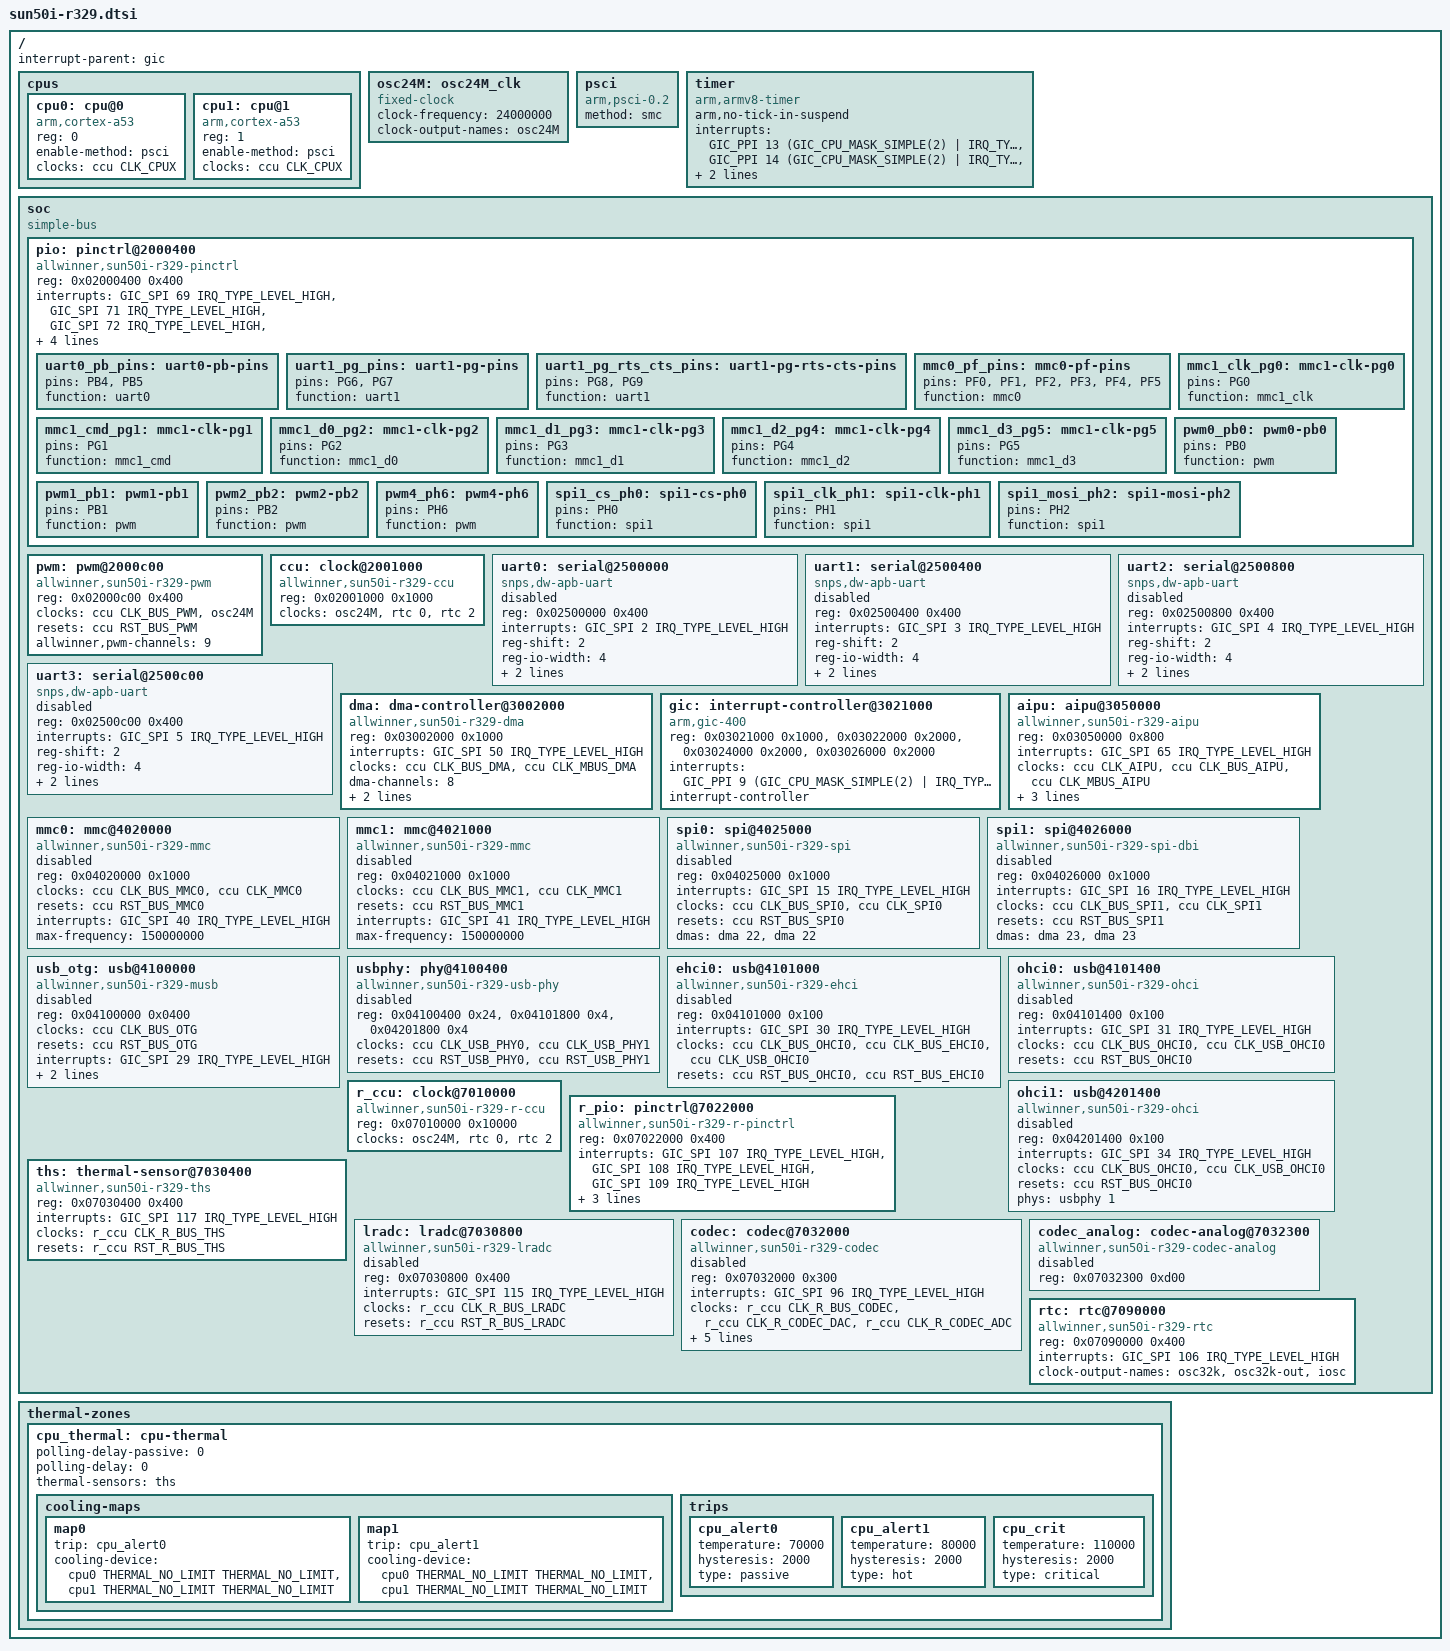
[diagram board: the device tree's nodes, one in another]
// SPDX-License-Identifier: (GPL-2.0+ OR MIT)
// Copyright (c) 2021 Sipeed

#include <dt-bindings/interrupt-controller/arm-gic.h>
#include <dt-bindings/clock/sun50i-r329-ccu.h>
#include <dt-bindings/reset/sun50i-r329-ccu.h>
#include <dt-bindings/clock/sun50i-r329-r-ccu.h>
#include <dt-bindings/reset/sun50i-r329-r-ccu.h>
#include <dt-bindings/thermal/thermal.h>

/ {
	interrupt-parent = <&gic>;
	#address-cells = <1>;
	#size-cells = <1>;

	cpus {
		#address-cells = <1>;
		#size-cells = <0>;

		cpu0: cpu@0 {
			compatible = "arm,cortex-a53";
			device_type = "cpu";
			reg = <0>;
			enable-method = "psci";
			clocks = <&ccu CLK_CPUX>;
			clock-names = "cpu";
			#cooling-cells = <2>;
		};

		cpu1: cpu@1 {
			compatible = "arm,cortex-a53";
			device_type = "cpu";
			reg = <1>;
			enable-method = "psci";
			clocks = <&ccu CLK_CPUX>;
			clock-names = "cpu";
			#cooling-cells = <2>;
		};
	};

	osc24M: osc24M_clk {
		#clock-cells = <0>;
		compatible = "fixed-clock";
		clock-frequency = <24000000>;
		clock-output-names = "osc24M";
	};

	psci {
		compatible = "arm,psci-0.2";
		method = "smc";
	};

	timer {
		compatible = "arm,armv8-timer";
		arm,no-tick-in-suspend;
		interrupts = <GIC_PPI 13
			(GIC_CPU_MASK_SIMPLE(2) | IRQ_TYPE_LEVEL_HIGH)>,
			     <GIC_PPI 14
			(GIC_CPU_MASK_SIMPLE(2) | IRQ_TYPE_LEVEL_HIGH)>,
			     <GIC_PPI 11
			(GIC_CPU_MASK_SIMPLE(2) | IRQ_TYPE_LEVEL_HIGH)>,
			     <GIC_PPI 10
			(GIC_CPU_MASK_SIMPLE(2) | IRQ_TYPE_LEVEL_HIGH)>;
	};

	soc {
		compatible = "simple-bus";
		#address-cells = <1>;
		#size-cells = <1>;
		ranges;

		pio: pinctrl@2000400 {
			compatible = "allwinner,sun50i-r329-pinctrl";
			reg = <0x02000400 0x400>;
			interrupts = <GIC_SPI 69 IRQ_TYPE_LEVEL_HIGH>,
				     <GIC_SPI 71 IRQ_TYPE_LEVEL_HIGH>,
				     <GIC_SPI 72 IRQ_TYPE_LEVEL_HIGH>,
				     <GIC_SPI 73 IRQ_TYPE_LEVEL_HIGH>;
			clocks = <&ccu CLK_APB1>, <&osc24M>, <&rtc 0>;
			clock-names = "apb", "hosc", "losc";
			gpio-controller;
			#gpio-cells = <3>;
			interrupt-controller;
			#interrupt-cells = <3>;

			uart0_pb_pins: uart0-pb-pins {
				pins = "PB4", "PB5";
				function = "uart0";
			};

			uart1_pg_pins: uart1-pg-pins {
				pins = "PG6", "PG7";
				function = "uart1";
			};

			uart1_pg_rts_cts_pins: uart1-pg-rts-cts-pins {
				pins = "PG8", "PG9";
				function = "uart1";
			};

			mmc0_pf_pins: mmc0-pf-pins {
				pins = "PF0", "PF1", "PF2",
				       "PF3", "PF4", "PF5";
				function = "mmc0";
			};

			mmc1_clk_pg0: mmc1-clk-pg0 {
				pins = "PG0";
				function = "mmc1_clk";
			};

			mmc1_cmd_pg1: mmc1-clk-pg1 {
				pins = "PG1";
				function = "mmc1_cmd";
			};

			mmc1_d0_pg2: mmc1-clk-pg2 {
				pins = "PG2";
				function = "mmc1_d0";
			};

			mmc1_d1_pg3: mmc1-clk-pg3 {
				pins = "PG3";
				function = "mmc1_d1";
			};

			mmc1_d2_pg4: mmc1-clk-pg4 {
				pins = "PG4";
				function = "mmc1_d2";
			};

			mmc1_d3_pg5: mmc1-clk-pg5 {
				pins = "PG5";
				function = "mmc1_d3";
			};

			pwm0_pb0: pwm0-pb0 {
				pins = "PB0";
				function = "pwm";
			};

			pwm1_pb1: pwm1-pb1 {
				pins = "PB1";
				function = "pwm";
			};

			pwm2_pb2: pwm2-pb2 {
				pins = "PB2";
				function = "pwm";
			};

			pwm4_ph6: pwm4-ph6 {
				pins = "PH6";
				function = "pwm";
			};

			spi1_cs_ph0: spi1-cs-ph0 {
				pins = "PH0";
				function = "spi1";
			};

			spi1_clk_ph1: spi1-clk-ph1 {
				pins = "PH1";
				function = "spi1";
			};

			spi1_mosi_ph2: spi1-mosi-ph2 {
				pins = "PH2";
				function = "spi1";
			};
		};

		pwm: pwm@2000c00 {
			compatible = "allwinner,sun50i-r329-pwm";
			reg = <0x02000c00 0x400>;
			clocks = <&ccu CLK_BUS_PWM>, <&osc24M>;
			clock-names = "bus", "hosc";
			resets = <&ccu RST_BUS_PWM>;
			allwinner,pwm-channels = <9>;
			#pwm-cells = <3>;
		};

		ccu: clock@2001000 {
			compatible = "allwinner,sun50i-r329-ccu";
			reg = <0x02001000 0x1000>;
			clocks = <&osc24M>, <&rtc 0>, <&rtc 2>;
			clock-names = "hosc", "losc", "iosc";
			#clock-cells = <1>;
			#reset-cells = <1>;
		};

		uart0: serial@2500000 {
			compatible = "snps,dw-apb-uart";
			reg = <0x02500000 0x400>;
			interrupts = <GIC_SPI 2 IRQ_TYPE_LEVEL_HIGH>;
			reg-shift = <2>;
			reg-io-width = <4>;
			clocks = <&ccu CLK_BUS_UART0>;
			resets = <&ccu RST_BUS_UART0>;
			status = "disabled";
		};

		uart1: serial@2500400 {
			compatible = "snps,dw-apb-uart";
			reg = <0x02500400 0x400>;
			interrupts = <GIC_SPI 3 IRQ_TYPE_LEVEL_HIGH>;
			reg-shift = <2>;
			reg-io-width = <4>;
			clocks = <&ccu CLK_BUS_UART1>;
			resets = <&ccu RST_BUS_UART1>;
			status = "disabled";
		};

		uart2: serial@2500800 {
			compatible = "snps,dw-apb-uart";
			reg = <0x02500800 0x400>;
			interrupts = <GIC_SPI 4 IRQ_TYPE_LEVEL_HIGH>;
			reg-shift = <2>;
			reg-io-width = <4>;
			clocks = <&ccu CLK_BUS_UART2>;
			resets = <&ccu RST_BUS_UART2>;
			status = "disabled";
		};

		uart3: serial@2500c00 {
			compatible = "snps,dw-apb-uart";
			reg = <0x02500c00 0x400>;
			interrupts = <GIC_SPI 5 IRQ_TYPE_LEVEL_HIGH>;
			reg-shift = <2>;
			reg-io-width = <4>;
			clocks = <&ccu CLK_BUS_UART3>;
			resets = <&ccu RST_BUS_UART3>;
			status = "disabled";
		};

		dma: dma-controller@3002000 {
			compatible = "allwinner,sun50i-r329-dma",
				     "allwinner,sun50i-a100-dma";
			reg = <0x03002000 0x1000>;
			interrupts = <GIC_SPI 50 IRQ_TYPE_LEVEL_HIGH>;
			clocks = <&ccu CLK_BUS_DMA>, <&ccu CLK_MBUS_DMA>;
			clock-names = "bus", "mbus";
			dma-channels = <8>;
			dma-requests = <54>;
			resets = <&ccu RST_BUS_DMA>;
			#dma-cells = <1>;
		};

		gic: interrupt-controller@3021000 {
			compatible = "arm,gic-400";
			reg = <0x03021000 0x1000>,
			      <0x03022000 0x2000>,
			      <0x03024000 0x2000>,
			      <0x03026000 0x2000>;
			interrupts = <GIC_PPI 9 (GIC_CPU_MASK_SIMPLE(2) | IRQ_TYPE_LEVEL_HIGH)>;
			interrupt-controller;
			#interrupt-cells = <3>;
		};

		aipu: aipu@3050000 {
			compatible = "allwinner,sun50i-r329-aipu",
				     "armchina,zhouyi-v1";
			reg = <0x03050000 0x800>;
			interrupts = <GIC_SPI 65 IRQ_TYPE_LEVEL_HIGH>;
			clocks = <&ccu CLK_AIPU>, <&ccu CLK_BUS_AIPU>, <&ccu CLK_MBUS_AIPU>;
			clock-names = "core", "bus", "mbus";
			resets = <&ccu RST_BUS_AIPU>;
			assigned-clocks = <&ccu CLK_AIPU>;
			assigned-clock-rates = <600000000>;
		};

		mmc0: mmc@4020000 {
			compatible = "allwinner,sun50i-r329-mmc";
			reg = <0x04020000 0x1000>;
			clocks = <&ccu CLK_BUS_MMC0>, <&ccu CLK_MMC0>;
			clock-names = "ahb", "mmc";
			resets = <&ccu RST_BUS_MMC0>;
			reset-names = "ahb";
			interrupts = <GIC_SPI 40 IRQ_TYPE_LEVEL_HIGH>;
			max-frequency = <150000000>;
			status = "disabled";
			#address-cells = <1>;
			#size-cells = <0>;
		};

		mmc1: mmc@4021000 {
			compatible = "allwinner,sun50i-r329-mmc";
			reg = <0x04021000 0x1000>;
			clocks = <&ccu CLK_BUS_MMC1>, <&ccu CLK_MMC1>;
			clock-names = "ahb", "mmc";
			resets = <&ccu RST_BUS_MMC1>;
			reset-names = "ahb";
			interrupts = <GIC_SPI 41 IRQ_TYPE_LEVEL_HIGH>;
			max-frequency = <150000000>;
			status = "disabled";
			#address-cells = <1>;
			#size-cells = <0>;
		};

		spi0: spi@4025000 {
			compatible = "allwinner,sun50i-r329-spi";
			reg = <0x04025000 0x1000>;
			interrupts = <GIC_SPI 15 IRQ_TYPE_LEVEL_HIGH>;
			clocks = <&ccu CLK_BUS_SPI0>, <&ccu CLK_SPI0>;
			clock-names = "ahb", "mod";
			resets = <&ccu RST_BUS_SPI0>;
			dmas = <&dma 22>, <&dma 22>;
			dma-names = "rx", "tx";
			status = "disabled";
			#address-cells = <1>;
			#size-cells = <0>;
		};

		spi1: spi@4026000 {
			compatible = "allwinner,sun50i-r329-spi-dbi";
			reg = <0x04026000 0x1000>;
			interrupts = <GIC_SPI 16 IRQ_TYPE_LEVEL_HIGH>;
			clocks = <&ccu CLK_BUS_SPI1>, <&ccu CLK_SPI1>;
			clock-names = "ahb", "mod";
			resets = <&ccu RST_BUS_SPI1>;
			dmas = <&dma 23>, <&dma 23>;
			dma-names = "rx", "tx";
			status = "disabled";
			#address-cells = <1>;
			#size-cells = <0>;
		};

		usb_otg: usb@4100000 {
			compatible = "allwinner,sun50i-r329-musb",
				     "allwinner,sun8i-a33-musb";
			reg = <0x04100000 0x0400>;
			clocks = <&ccu CLK_BUS_OTG>;
			resets = <&ccu RST_BUS_OTG>;
			interrupts = <GIC_SPI 29 IRQ_TYPE_LEVEL_HIGH>;
			interrupt-names = "mc";
			phys = <&usbphy 0>;
			phy-names = "usb";
			extcon = <&usbphy 0>;
			status = "disabled";
		};

		usbphy: phy@4100400 {
			compatible = "allwinner,sun50i-r329-usb-phy";
			reg = <0x04100400 0x24>,
			      <0x04101800 0x4>,
			      <0x04201800 0x4>;
			reg-names = "phy_ctrl",
				    "pmu0",
				    "pmu1";
			clocks = <&ccu CLK_USB_PHY0>,
				 <&ccu CLK_USB_PHY1>;
			clock-names = "usb0_phy",
				      "usb1_phy";
			resets = <&ccu RST_USB_PHY0>,
				 <&ccu RST_USB_PHY1>;
			reset-names = "usb0_reset",
				      "usb1_reset";
			status = "disabled";
			#phy-cells = <1>;
		};

		ehci0: usb@4101000 {
			compatible = "allwinner,sun50i-r329-ehci", "generic-ehci";
			reg = <0x04101000 0x100>;
			interrupts = <GIC_SPI 30 IRQ_TYPE_LEVEL_HIGH>;
			clocks = <&ccu CLK_BUS_OHCI0>,
				 <&ccu CLK_BUS_EHCI0>,
				 <&ccu CLK_USB_OHCI0>;
			resets = <&ccu RST_BUS_OHCI0>,
				 <&ccu RST_BUS_EHCI0>;
			status = "disabled";
		};

		ohci0: usb@4101400 {
			compatible = "allwinner,sun50i-r329-ohci", "generic-ohci";
			reg = <0x04101400 0x100>;
			interrupts = <GIC_SPI 31 IRQ_TYPE_LEVEL_HIGH>;
			clocks = <&ccu CLK_BUS_OHCI0>,
				 <&ccu CLK_USB_OHCI0>;
			resets = <&ccu RST_BUS_OHCI0>;
			status = "disabled";
		};

		ohci1: usb@4201400 {
			compatible = "allwinner,sun50i-r329-ohci", "generic-ohci";
			reg = <0x04201400 0x100>;
			interrupts = <GIC_SPI 34 IRQ_TYPE_LEVEL_HIGH>;
			clocks = <&ccu CLK_BUS_OHCI0>,
				 <&ccu CLK_USB_OHCI0>;
			resets = <&ccu RST_BUS_OHCI0>;
			phys = <&usbphy 1>;
			phy-names = "usb";
			status = "disabled";
		};

		r_ccu: clock@7010000 {
			compatible = "allwinner,sun50i-r329-r-ccu";
			reg = <0x07010000 0x10000>;
			clocks = <&osc24M>, <&rtc 0>, <&rtc 2>;
			clock-names = "hosc", "losc", "iosc";
			#clock-cells = <1>;
			#reset-cells = <1>;
		};

		r_pio: pinctrl@7022000 {
			compatible = "allwinner,sun50i-r329-r-pinctrl";
			reg = <0x07022000 0x400>;
			interrupts = <GIC_SPI 107 IRQ_TYPE_LEVEL_HIGH>,
				     <GIC_SPI 108 IRQ_TYPE_LEVEL_HIGH>,
				     <GIC_SPI 109 IRQ_TYPE_LEVEL_HIGH>;
			clocks = <&r_ccu CLK_R_APB1>, <&osc24M>, <&rtc 0>;
			clock-names = "apb", "hosc", "losc";
			gpio-controller;
			#gpio-cells = <3>;
			interrupt-controller;
			#interrupt-cells = <3>;
		};

		ths: thermal-sensor@7030400 {
			compatible = "allwinner,sun50i-r329-ths";
			reg = <0x07030400 0x400>;
			interrupts = <GIC_SPI 117 IRQ_TYPE_LEVEL_HIGH>;
			clocks = <&r_ccu CLK_R_BUS_THS>;
			clock-names = "bus";
			resets = <&r_ccu RST_R_BUS_THS>;
			#thermal-sensor-cells = <0>;
		};

		lradc: lradc@7030800 {
			compatible = "allwinner,sun50i-r329-lradc";
			reg = <0x07030800 0x400>;
			interrupts = <GIC_SPI 115 IRQ_TYPE_LEVEL_HIGH>;
			clocks = <&r_ccu CLK_R_BUS_LRADC>;
			resets = <&r_ccu RST_R_BUS_LRADC>;
			status = "disabled";
		};

		codec: codec@7032000 {
			#sound-dai-cells = <0>;
			compatible = "allwinner,sun50i-r329-codec";
			reg = <0x07032000 0x300>;
			interrupts = <GIC_SPI 96 IRQ_TYPE_LEVEL_HIGH>;
			clocks = <&r_ccu CLK_R_BUS_CODEC>, <&r_ccu CLK_R_CODEC_DAC>, <&r_ccu CLK_R_CODEC_ADC>;
			clock-names = "apb", "dac", "adc";
			resets = <&r_ccu RST_R_BUS_CODEC>;
			dmas = <&dma 6>, <&dma 6>;
			dma-names = "rx", "tx";
			allwinner,codec-analog-controls = <&codec_analog>;
			assigned-clocks = <&r_ccu CLK_PLL_AUDIO1>;
			assigned-clock-rates = <22579200>;
			status = "disabled";
		};

		codec_analog: codec-analog@7032300 {
			compatible = "allwinner,sun50i-r329-codec-analog";
			reg = <0x07032300 0xd00>;
			status = "disabled";
		};

		rtc: rtc@7090000 {
			compatible = "allwinner,sun50i-r329-rtc";
			reg = <0x07090000 0x400>;
			interrupts = <GIC_SPI 106 IRQ_TYPE_LEVEL_HIGH>;
			clock-output-names = "osc32k", "osc32k-out", "iosc";
			#clock-cells = <1>;
		};
	};

	thermal-zones {
		cpu_thermal: cpu-thermal {
			/* milliseconds */
			polling-delay-passive = <0>;
			polling-delay = <0>;
			thermal-sensors = <&ths>;

			cooling-maps {
				map0 {
					trip = <&cpu_alert0>;
					cooling-device = <&cpu0 THERMAL_NO_LIMIT THERMAL_NO_LIMIT>,
							 <&cpu1 THERMAL_NO_LIMIT THERMAL_NO_LIMIT>;
				};
				map1 {
					trip = <&cpu_alert1>;
					cooling-device = <&cpu0 THERMAL_NO_LIMIT THERMAL_NO_LIMIT>,
							 <&cpu1 THERMAL_NO_LIMIT THERMAL_NO_LIMIT>;
				};
			};

			trips {
				cpu_alert0: cpu_alert0 {
					/* milliCelsius */
					temperature = <70000>;
					hysteresis = <2000>;
					type = "passive";
				};

				cpu_alert1: cpu_alert1 {
					/* milliCelsius */
					temperature = <80000>;
					hysteresis = <2000>;
					type = "hot";
				};

				cpu_crit: cpu_crit {
					/* milliCelsius */
					temperature = <110000>;
					hysteresis = <2000>;
					type = "critical";
				};
			};
		};
	};
};
